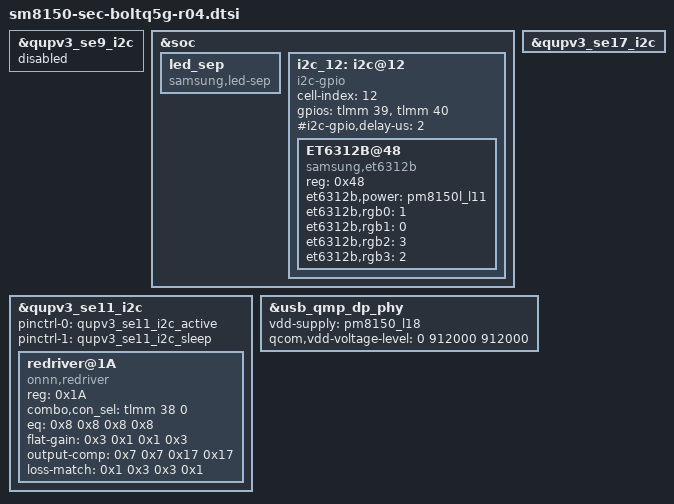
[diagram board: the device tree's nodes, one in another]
/* Copyright (c) 2016-2017, The Linux Foundation. All rights reserved.
 *
 * This program is free software; you can redistribute it and/or modify
 * it under the terms of the GNU General Public License version 2 and
 * only version 2 as published by the Free Software Foundation.
 *
 * This program is distributed in the hope that it will be useful,
 * but WITHOUT ANY WARRANTY; without even the implied warranty of
 * MERCHANTABILITY or FITNESS FOR A PARTICULAR PURPOSE.  See the
 * GNU General Public License for more details.
 */

#include "sm8150-sec-boltq5g-common.dtsi"

&qupv3_se9_i2c {
	status = "disabled";
};

&soc {
	led_sep {
		compatible = "samsung,led-sep";
	};

	i2c_12: i2c@12 { /* SW I2C */
		status = "ok";

		cell-index = <12>;
		compatible = "i2c-gpio";
		gpios = <&tlmm 39 0 /* sda */
			 &tlmm 40 0 /* scl */
		>;
		#i2c-gpio,delay-us = <2>;
		#address-cells = <1>;
		#size-cells = <0>;

		ET6312B@48 {
			compatible = "samsung,et6312b";
			reg = <0x48>;
	
			et6312b,power = "pm8150l_l11";

			et6312b,rgb0 = <1>;
			et6312b,rgb1 = <0>;
			et6312b,rgb2 = <3>;
			et6312b,rgb3 = <2>;
		};
	};
};

&qupv3_se17_i2c {
	status = "ok";
};

&qupv3_se11_i2c {
	status = "ok";

	pinctrl-names = "default", "sleep";
	pinctrl-0 = <&qupv3_se11_i2c_active>;
	pinctrl-1 = <&qupv3_se11_i2c_sleep>;

	redriver@1A {
		compatible = "onnn,redriver";
		reg = <0x1A>;
		combo,con_sel = <&tlmm 38 0>;
		eq = /bits/ 8 <0x8 0x8 0x8 0x8>;
		flat-gain = /bits/ 8 <0x3 0x1 0x1 0x3>;
		output-comp = /bits/ 8 <0x7 0x7 0x17 0x17>;
		loss-match = /bits/ 8 <0x1 0x3 0x3 0x1>;
	};
};

&usb_qmp_dp_phy {
	vdd-supply = <&pm8150_l18>;
	qcom,vdd-voltage-level = <0 912000 912000>;
};
